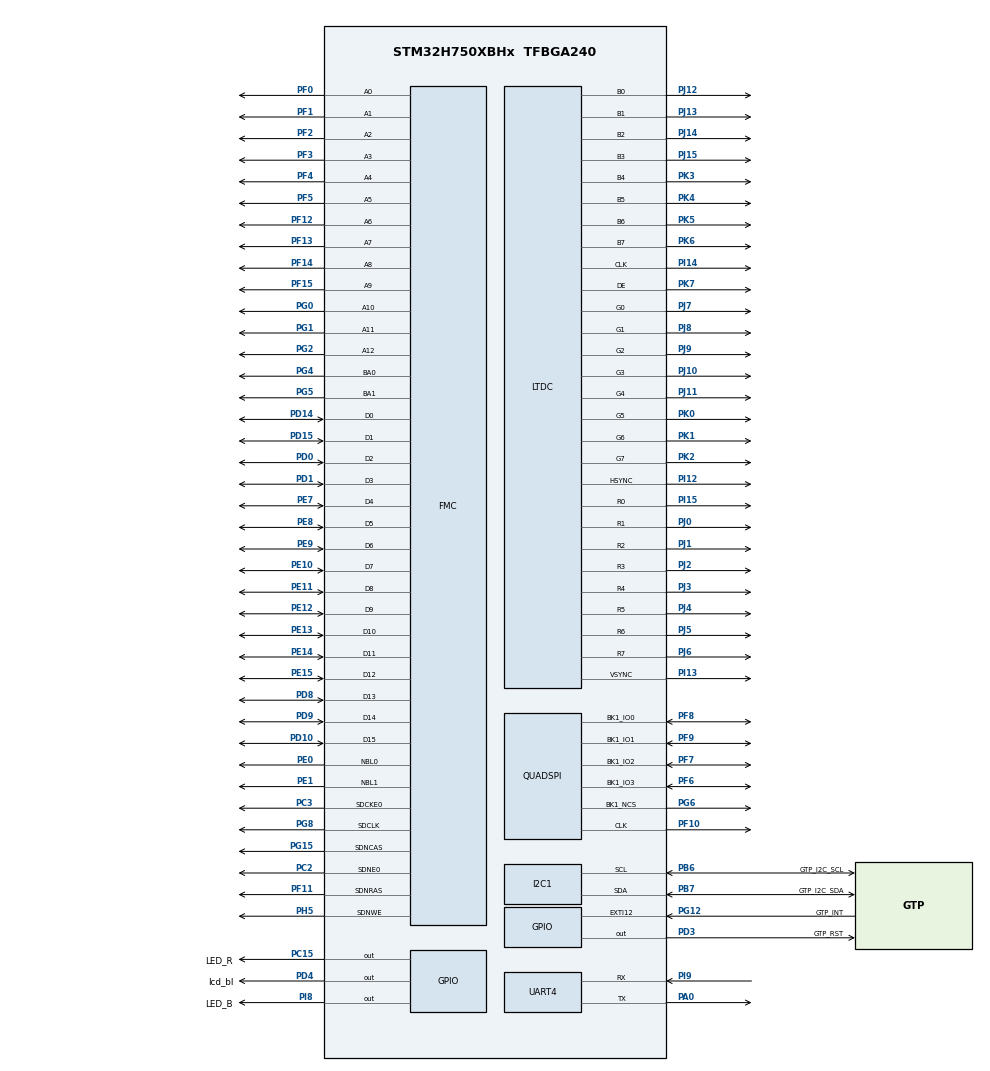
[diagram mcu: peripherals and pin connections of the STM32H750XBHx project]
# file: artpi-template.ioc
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DMA2D.ColorMode=DMA2D_OUTPUT_RGB565
FMC.CASLatency1=FMC_SDRAM_CAS_LATENCY_2
FMC.ColumnBitsNumber1=FMC_SDRAM_COLUMN_BITS_NUM_9
FMC.ExitSelfRefreshDelay1=8
FMC.LoadToActiveDelay1=2
FMC.RCDDelay1=2
FMC.RPDelay1=2
FMC.RowCycleDelay1=6
FMC.SDClockPeriod1=FMC_SDRAM_CLOCK_PERIOD_2
FMC.SelfRefreshTime1=6
I2C1.Timing=0x10C0ECFF
LTDC.ActiveW=800
LTDC.Alpha0_L0=0xff
LTDC.Alpha_L0=0xff
LTDC.FBStartAdress_L0=0xc0000000
LTDC.Green=255
LTDC.Green_L0=0
LTDC.HBP=140
LTDC.HFP=160
LTDC.HSync=20
LTDC.ImageHeight_L0=480
LTDC.ImageWidth_L0=800
LTDC.Layers=0
LTDC.PixelFormat_L0=LTDC_PIXEL_FORMAT_RGB565
LTDC.Red_L0=255
LTDC.VBP=12
LTDC.VFP=12
LTDC.VSync=3
LTDC.WindowX1_L0=800
LTDC.WindowY1_L0=480
Mcu.Family=STM32H7
Mcu.Name=STM32H750XBHx
Mcu.Package=TFBGA240
NVIC.EXTI15_10_IRQn=true\:0\:0\:false\:false\:true\:true\:true
NVIC.PriorityGroup=NVIC_PRIORITYGROUP_4
PA0.Mode=Asynchronous
PA0.Signal=UART4_TX
PA13\ (JTMS/SWDIO).Mode=Serial_Wire
PA13\ (JTMS/SWDIO).Signal=DEBUG_JTMS-SWDIO
PA14\ (JTCK/SWCLK).Mode=Serial_Wire
PA14\ (JTCK/SWCLK).Signal=DEBUG_JTCK-SWCLK
PB6.GPIO_Label=GTP_I2C_SCL
PB6.Mode=I2C
PB6.Signal=I2C1_SCL
PB7.GPIO_Label=GTP_I2C_SDA
PB7.Mode=I2C
PB7.Signal=I2C1_SDA
PC15-OSC32_OUT\ (OSC32_OUT).GPIO_Label=LED_R
PC15-OSC32_OUT\ (OSC32_OUT).Signal=GPIO_Output
PC2.Mode=SdramChipSelect1_1
PC2.Signal=FMC_SDNE0
PC3.Mode=SdramChipSelect1_1
PC3.Signal=FMC_SDCKE0
PD0.Signal=FMC_D2_DA2
PD1.Signal=FMC_D3_DA3
PD10.Signal=FMC_D15_DA15
PD14.Signal=FMC_D0_DA0
PD15.Signal=FMC_D1_DA1
PD3.GPIO_Label=GTP_RST
PD3.Signal=GPIO_Output
PD4.GPIO_Label=lcd_bl
PD4.Signal=GPIO_Output
PD8.Signal=FMC_D13_DA13
PD9.Signal=FMC_D14_DA14
PE0.Signal=FMC_NBL0
PE1.Signal=FMC_NBL1
PE10.Signal=FMC_D7_DA7
PE11.Signal=FMC_D8_DA8
PE12.Signal=FMC_D9_DA9
PE13.Signal=FMC_D10_DA10
PE14.Signal=FMC_D11_DA11
PE15.Signal=FMC_D12_DA12
PE7.Signal=FMC_D4_DA4
PE8.Signal=FMC_D5_DA5
PE9.Signal=FMC_D6_DA6
PF0.Signal=FMC_A0
PF1.Signal=FMC_A1
PF10.Mode=Single Bank 1
PF10.Signal=QUADSPI_CLK
PF11.Signal=FMC_SDNRAS
PF12.Signal=FMC_A6
PF13.Signal=FMC_A7
PF14.Signal=FMC_A8
PF15.Signal=FMC_A9
PF2.Signal=FMC_A2
PF3.Signal=FMC_A3
PF4.Signal=FMC_A4
PF5.Signal=FMC_A5
PF6.Mode=Single Bank 1
PF6.Signal=QUADSPI_BK1_IO3
PF7.Mode=Single Bank 1
PF7.Signal=QUADSPI_BK1_IO2
PF8.Mode=Single Bank 1
PF8.Signal=QUADSPI_BK1_IO0
PF9.Mode=Single Bank 1
PF9.Signal=QUADSPI_BK1_IO1
PG0.Signal=FMC_A10
PG1.Signal=FMC_A11
PG12.GPIO_Label=GTP_INT
PG12.Signal=GPXTI12
PG15.Signal=FMC_SDNCAS
PG2.Signal=FMC_A12
PG4.Signal=FMC_A14_BA0
PG5.Signal=FMC_A15_BA1
PG6.Mode=Single Bank 1
PG6.Signal=QUADSPI_BK1_NCS
PG8.Signal=FMC_SDCLK
PH0-OSC_IN\ (PH0).Mode=HSE-External-Oscillator
PH0-OSC_IN\ (PH0).Signal=RCC_OSC_IN
PH1-OSC_OUT\ (PH1).Mode=HSE-External-Oscillator
PH1-OSC_OUT\ (PH1).Signal=RCC_OSC_OUT
PH5.Signal=FMC_SDNWE
PI12.Mode=RGB888
PI12.Signal=LTDC_HSYNC
PI13.Mode=RGB888
PI13.Signal=LTDC_VSYNC
PI14.Mode=RGB888
PI14.Signal=LTDC_CLK
PI15.Mode=RGB888
PI15.Signal=LTDC_R0
PI8.GPIO_Label=LED_B
PI8.Signal=GPIO_Output
PI9.Mode=Asynchronous
PI9.Signal=UART4_RX
PJ0.Mode=RGB888
PJ0.Signal=LTDC_R1
PJ1.Mode=RGB888
PJ1.Signal=LTDC_R2
PJ10.Mode=RGB888
PJ10.Signal=LTDC_G3
PJ11.Mode=RGB888
PJ11.Signal=LTDC_G4
PJ12.Mode=RGB888
PJ12.Signal=LTDC_B0
PJ13.Mode=RGB888
PJ13.Signal=LTDC_B1
PJ14.Mode=RGB888
PJ14.Signal=LTDC_B2
PJ15.Mode=RGB888
PJ15.Signal=LTDC_B3
PJ2.Mode=RGB888
PJ2.Signal=LTDC_R3
PJ3.Mode=RGB888
PJ3.Signal=LTDC_R4
PJ4.Mode=RGB888
PJ4.Signal=LTDC_R5
PJ5.Mode=RGB888
PJ5.Signal=LTDC_R6
PJ6.Mode=RGB888
PJ6.Signal=LTDC_R7
PJ7.Mode=RGB888
PJ7.Signal=LTDC_G0
PJ8.Mode=RGB888
PJ8.Signal=LTDC_G1
PJ9.Mode=RGB888
PJ9.Signal=LTDC_G2
PK0.Mode=RGB888
PK0.Signal=LTDC_G5
PK1.Mode=RGB888
PK1.Signal=LTDC_G6
PK2.Mode=RGB888
PK2.Signal=LTDC_G7
PK3.Mode=RGB888
PK3.Signal=LTDC_B4
PK4.Mode=RGB888
PK4.Signal=LTDC_B5
PK5.Mode=RGB888
PK5.Signal=LTDC_B6
PK6.Mode=RGB888
PK6.Signal=LTDC_B7
PK7.Mode=RGB888
PK7.Signal=LTDC_DE
ProjectManager.HeapSize=0x200
ProjectManager.StackSize=0x400
ProjectManager.TargetToolchain=MDK-ARM V5.32
QUADSPI.ChipSelectHighTime=QSPI_CS_HIGH_TIME_5_CYCLE
QUADSPI.ClockPrescaler=1
QUADSPI.FifoThreshold=4
QUADSPI.FlashSize=23
QUADSPI.SampleShifting=QSPI_SAMPLE_SHIFTING_HALFCYCLE
RCC.ADCFreq_Value=64000000
RCC.APB1Freq_Value=100000000
RCC.APB2Freq_Value=100000000
RCC.APB3Freq_Value=100000000
RCC.APB4Freq_Value=100000000
RCC.CSICalibrationValue=16
RCC.CortexFreq_Value=400000000
RCC.D1PPRE=RCC_APB3_DIV2
RCC.D2PPRE1=RCC_APB1_DIV2
RCC.D2PPRE2=RCC_APB2_DIV2
RCC.D3PPRE=RCC_APB4_DIV2
RCC.DIVM1=5
RCC.DIVM2=25
RCC.DIVM3=5
RCC.DIVN1=160
RCC.DIVN2=128
RCC.DIVN3=50
RCC.DIVR3=10
RCC.HCLKFreq_Value=200000000
RCC.HPRE=RCC_HCLK_DIV2
RCC.HSICalibrationValue=32
RCC.PLLSourceVirtual=RCC_PLLSOURCE_HSE
RCC.ProductRev=revV
RCC.SYSCLKFreq_VALUE=400000000
RCC.SYSCLKSource=RCC_SYSCLKSOURCE_PLLCLK
RCC.USART234578CLockSelection=RCC_USART234578CLKSOURCE_CSI
RCC.USBFreq_Value=400000000
SH.FMC_A0.0=FMC_A0,13b-sda1
SH.FMC_A1.0=FMC_A1,13b-sda1
SH.FMC_A10.0=FMC_A10,13b-sda1
SH.FMC_A11.0=FMC_A11,13b-sda1
SH.FMC_A12.0=FMC_A12,13b-sda1
SH.FMC_A14_BA0.0=FMC_BA0,FourSdramBanks1
SH.FMC_A15_BA1.0=FMC_BA1,FourSdramBanks1
SH.FMC_A2.0=FMC_A2,13b-sda1
SH.FMC_A3.0=FMC_A3,13b-sda1
SH.FMC_A4.0=FMC_A4,13b-sda1
SH.FMC_A5.0=FMC_A5,13b-sda1
SH.FMC_A6.0=FMC_A6,13b-sda1
SH.FMC_A7.0=FMC_A7,13b-sda1
SH.FMC_A8.0=FMC_A8,13b-sda1
SH.FMC_A9.0=FMC_A9,13b-sda1
SH.FMC_D0_DA0.0=FMC_D0,sd-16b-d1
SH.FMC_D10_DA10.0=FMC_D10,sd-16b-d1
SH.FMC_D11_DA11.0=FMC_D11,sd-16b-d1
SH.FMC_D12_DA12.0=FMC_D12,sd-16b-d1
SH.FMC_D13_DA13.0=FMC_D13,sd-16b-d1
SH.FMC_D14_DA14.0=FMC_D14,sd-16b-d1
SH.FMC_D15_DA15.0=FMC_D15,sd-16b-d1
SH.FMC_D1_DA1.0=FMC_D1,sd-16b-d1
SH.FMC_D2_DA2.0=FMC_D2,sd-16b-d1
SH.FMC_D3_DA3.0=FMC_D3,sd-16b-d1
SH.FMC_D4_DA4.0=FMC_D4,sd-16b-d1
SH.FMC_D5_DA5.0=FMC_D5,sd-16b-d1
SH.FMC_D6_DA6.0=FMC_D6,sd-16b-d1
SH.FMC_D7_DA7.0=FMC_D7,sd-16b-d1
SH.FMC_D8_DA8.0=FMC_D8,sd-16b-d1
SH.FMC_D9_DA9.0=FMC_D9,sd-16b-d1
SH.FMC_NBL0.0=FMC_NBL0,Sd2ByteEnable1
SH.FMC_NBL1.0=FMC_NBL1,Sd2ByteEnable1
SH.FMC_SDCLK.0=FMC_SDCLK,13b-sda1
SH.FMC_SDNCAS.0=FMC_SDNCAS,13b-sda1
SH.FMC_SDNRAS.0=FMC_SDNRAS,13b-sda1
SH.FMC_SDNWE.0=FMC_SDNWE,13b-sda1
VP_CRC_VS_CRC.Mode=CRC_Activate
VP_DMA2D_VS_DMA2D.Mode=DMA2D_Activate
board=custom

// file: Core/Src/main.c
/* USER CODE BEGIN Header */
/**
  ******************************************************************************
  * @file           : main.c
  * @brief          : Main program body
  ******************************************************************************
  * @attention
  *
  * Copyright (c) 2022 STMicroelectronics.
  * All rights reserved.
  *
  * This software is licensed under terms that can be found in the LICENSE file
  * in the root directory of this software component.
  * If no LICENSE file comes with this software, it is provided AS-IS.
  *
  ******************************************************************************
  */
/* USER CODE END Header */
#include "main.h"
#include "crc.h"
#include "dma2d.h"
#include "i2c.h"
#include "ltdc.h"
#include "quadspi.h"
#include "usart.h"
#include "gpio.h"
#include "fmc.h"

/* USER CODE BEGIN Includes */
#include <stdio.h>
#include "EventRecorder.h"
#include "perf_counter.h"

#include "bsp_i2c_touch.h"
#include "bsp_touch_gtxx.h"
#include "core_delay.h"

#include "lvgl.h"
#include "demos/lv_demos.h"
/* USER CODE END Includes */

/* USER CODE BEGIN PD */
void MX_SDRAM_InitEx(void);

void lv_port_indev_init(void);
void lv_port_disp_init(void);

extern void GTP_TouchProcess(void);

static void touchpad_init(void);
static void touchpad_read(lv_indev_drv_t * indev_drv, lv_indev_data_t * data);
static bool touchpad_is_pressed(void);
static void touchpad_get_xy(lv_coord_t * x, lv_coord_t * y);
/* USER CODE END PD */

/* USER CODE BEGIN PV */
unsigned int *dispbuf  = (unsigned int*)0xc0000000;
unsigned int tpx=0,tpy=0,tppressed = 0;
/* USER CODE END PV */

void SystemClock_Config(void);
/* USER CODE BEGIN PFP */
extern void QSPI_MemoryMapped(void);
/* USER CODE END PFP */

int main(void)
{

  /* MCU Configuration--------------------------------------------------------*/

  /* Reset of all peripherals, Initializes the Flash interface and the Systick. */
  HAL_Init();

  /* Configure the system clock */
  SystemClock_Config();

  /* USER CODE BEGIN SysInit */
	SystemCoreClock = 400000000ul;//400MHz
	init_cycle_counter(false);
  /* USER CODE END SysInit */

  /* Initialize all configured peripherals */
  MX_GPIO_Init();
	MX_QUADSPI_Init();

  MX_FMC_Init();
  MX_UART4_Init();
  MX_I2C1_Init();
  MX_DMA2D_Init();
  MX_CRC_Init();
  MX_LTDC_Init();
  /* USER CODE BEGIN 2 */

	HAL_GPIO_WritePin(lcd_bl_GPIO_Port,lcd_bl_Pin,1);
	printf("START!\r\n");
	GTP_Init_Panel();

	EventRecorderInitialize(EventRecordAll, 1U);
	EventRecorderStart();
	int32_t time=get_system_ms();
	int32_t time5ms=get_system_ms();
	int32_t time500ms=get_system_ms();
	int i;
	lv_init();
	lv_port_disp_init();
	lv_port_indev_init();
memset(dispbuf,0x55,800*480*2);
lv_demo_music();
//lv_demo_widgets();
//lv_demo_stress();
//lv_demo_benchmark();
  /* USER CODE END 2 */

  /* Infinite loop */
  /* USER CODE BEGIN WHILE */
  while (1)
  {

		time=get_system_ms();

		if(time>=(time5ms+5))
		{
			lv_tick_inc(5);
			lv_timer_handler();
			time5ms=get_system_ms();
		}

		if(time>=(time500ms+100))
		{
//			memset(dispbuf,0xff,800*480*2);
//			memset(dispbuf,i++,800*480*2);

			HAL_GPIO_TogglePin(LED_R_GPIO_Port,LED_R_Pin);
			time500ms=get_system_ms();
		}

//		HAL_GPIO_TogglePin(lcd_bl_GPIO_Port,lcd_bl_Pin);
    /* USER CODE END WHILE */

  }
}

void SystemClock_Config(void)
{
  RCC_OscInitTypeDef RCC_OscInitStruct = {0};
  RCC_ClkInitTypeDef RCC_ClkInitStruct = {0};

  /** Supply configuration update enable
  */
  HAL_PWREx_ConfigSupply(PWR_LDO_SUPPLY);
  /** Configure the main internal regulator output voltage
  */
  __HAL_PWR_VOLTAGESCALING_CONFIG(PWR_REGULATOR_VOLTAGE_SCALE1);

  while(!__HAL_PWR_GET_FLAG(PWR_FLAG_VOSRDY)) {}
  /** Macro to configure the PLL clock source
  */
  __HAL_RCC_PLL_PLLSOURCE_CONFIG(RCC_PLLSOURCE_HSE);
  /** Initializes the RCC Oscillators according to the specified parameters
  * in the RCC_OscInitTypeDef structure.
  */
  RCC_OscInitStruct.OscillatorType = RCC_OSCILLATORTYPE_CSI|RCC_OSCILLATORTYPE_HSE;
  RCC_OscInitStruct.HSEState = RCC_HSE_ON;
  RCC_OscInitStruct.CSIState = RCC_CSI_ON;
  RCC_OscInitStruct.CSICalibrationValue = 16;
  RCC_OscInitStruct.PLL.PLLState = RCC_PLL_ON;
  RCC_OscInitStruct.PLL.PLLSource = RCC_PLLSOURCE_HSE;
  RCC_OscInitStruct.PLL.PLLM = 5;
  RCC_OscInitStruct.PLL.PLLN = 160;
  RCC_OscInitStruct.PLL.PLLP = 2;
  RCC_OscInitStruct.PLL.PLLQ = 2;
  RCC_OscInitStruct.PLL.PLLR = 2;
  RCC_OscInitStruct.PLL.PLLRGE = RCC_PLL1VCIRANGE_2;
  RCC_OscInitStruct.PLL.PLLVCOSEL = RCC_PLL1VCOWIDE;
  RCC_OscInitStruct.PLL.PLLFRACN = 0;
  if (HAL_RCC_OscConfig(&RCC_OscInitStruct) != HAL_OK)
  {
    Error_Handler();
  }
  /** Initializes the CPU, AHB and APB buses clocks
  */
  RCC_ClkInitStruct.ClockType = RCC_CLOCKTYPE_HCLK|RCC_CLOCKTYPE_SYSCLK
                              |RCC_CLOCKTYPE_PCLK1|RCC_CLOCKTYPE_PCLK2
                              |RCC_CLOCKTYPE_D3PCLK1|RCC_CLOCKTYPE_D1PCLK1;
  RCC_ClkInitStruct.SYSCLKSource = RCC_SYSCLKSOURCE_PLLCLK;
  RCC_ClkInitStruct.SYSCLKDivider = RCC_SYSCLK_DIV1;
  RCC_ClkInitStruct.AHBCLKDivider = RCC_HCLK_DIV2;
  RCC_ClkInitStruct.APB3CLKDivider = RCC_APB3_DIV2;
  RCC_ClkInitStruct.APB1CLKDivider = RCC_APB1_DIV2;
  RCC_ClkInitStruct.APB2CLKDivider = RCC_APB2_DIV2;
  RCC_ClkInitStruct.APB4CLKDivider = RCC_APB4_DIV2;

  if (HAL_RCC_ClockConfig(&RCC_ClkInitStruct, FLASH_LATENCY_2) != HAL_OK)
  {
    Error_Handler();
  }
}

/* USER CODE BEGIN 4 */
void LTDC_Color_Fill(uint16_t sx,uint16_t sy,uint16_t ex,uint16_t ey,uint16_t *color)
{
	uint32_t psx,psy,pex,pey;	//以LCD面板为基准的坐标系,不随横竖屏变化而变化
	uint32_t timeout=0;
	uint16_t offline;
	uint32_t addr;
	//坐标系转换
//	if(lcdltdc.dir)	//横屏
//	{
		psx=sx;psy=sy;
		pex=ex;pey=ey;
//	}else			//竖屏
//	{
//		psx=sy;psy=lcdltdc.pheight-ex-1;
//		pex=ey;pey=lcdltdc.pheight-sx-1;
//	}

	//width 800
	offline=800-(pex-psx+1);
	addr=((unsigned int)dispbuf[0]+2*(800*psy+psx));
	RCC->AHB1ENR|=1<<23;			//使能DM2D时钟
	DMA2D->CR=0<<16;				//存储器到存储器模式
	DMA2D->FGPFCCR=0X02;	//设置颜色格式 rgb565
	DMA2D->FGOR=0;					//前景层行偏移为0
	DMA2D->OOR=offline;				//设置行偏移
	DMA2D->CR&=~(1<<0);				//先停止DMA2D
	DMA2D->FGMAR=(unsigned int)color;		//源地址
	DMA2D->OMAR=addr;				//输出存储器地址
	DMA2D->NLR=(pey-psy+1)|((pex-psx+1)<<16);	//设定行数寄存器
	DMA2D->CR|=1<<0;				//启动DMA2D
	while((DMA2D->ISR&(1<<1))==0)	//等待传输完成
	{
		timeout++;
		if(timeout>0X1FFFFF)break;	//超时退出
	}
	DMA2D->IFCR|=1<<1;				//清除传输完成标志
}
#if 0
#define GLCD_WIDTH     800
#define GLCD_HEIGHT    480
#define LCD_DB_ADDR   0xC0000000
#define LCD_DB_PTR    ((volatile uint16_t *)LCD_DB_ADDR)

int32_t GLCD_DrawBitmap (uint32_t x,
                         uint32_t y,
                         uint32_t width,
                         uint32_t height,
                         const uint8_t *bitmap)
{
    volatile uint16_t *phwDes = LCD_DB_PTR + y * GLCD_WIDTH + x;
    const uint16_t *phwSrc = (const uint16_t *)bitmap;
    for (int_fast16_t i = 0; i < height; i++) {
        memcpy ((uint16_t *)phwDes, phwSrc, width * 2);
        phwSrc += width;
        phwDes += GLCD_WIDTH;
    }

    return 0;
}
#endif
void my_disp_flush(lv_disp_drv_t * disp, const lv_area_t * area, lv_color_t * color_p)
{

		uint32_t  height = area->y2 - area->y1;
		uint32_t  width= area->x2 - area->x1;
		uint32_t  x=area->x1;
		uint32_t  y=area->y1;

//		GLCD_DrawBitmap(x,width,y,height, (const uint8_t *)color_p);
//		LTDC_Color_Fill(area->x1,area->x2,area->y1,area->y2,(uint16_t*)color_p);

    lv_disp_flush_ready(disp);         /* Indicate you are ready with the flushing*/
}

void lv_port_disp_init(void)
{
	#define DISP_HOR_RES 800//800
	#define DISP_VER_RES 480//480

	static lv_disp_draw_buf_t draw_buf;
	//__attribute__((section(".ARM.__at_0x24000000")))
__attribute__((section(".ARM.__at_0xc0000000")))	static lv_color_t buf1[DISP_HOR_RES * DISP_VER_RES] ;// __attribute__((at(0Xc0001000)));
	/*Declare a buffer for 1/10 screen size*/
	lv_disp_draw_buf_init(&draw_buf, buf1, NULL, DISP_HOR_RES * DISP_VER_RES );
	/*Initialize the display buffer.*/

	static lv_disp_drv_t disp_drv;        /*Descriptor of a display driver*/
	lv_disp_drv_init(&disp_drv);          /*Basic initialization*/
	disp_drv.flush_cb = my_disp_flush;    /*Set your driver function*/
	disp_drv.draw_buf = &draw_buf;        /*Assign the buffer to the display*/
	disp_drv.hor_res = DISP_HOR_RES;   /*Set the horizontal resolution of the display*/
	disp_drv.ver_res = DISP_VER_RES;   /*Set the vertical resolution of the display*/
	disp_drv.full_refresh = 1;
	disp_drv.direct_mode = 1;
	lv_disp_drv_register(&disp_drv);      /*Finally register the driver*/
}

/*------------------
 * Touchpad
 * -----------------*/
lv_indev_t * indev_touchpad;

/*Initialize your touchpad*/
static void touchpad_init(void)
{
    /*Your code comes here*/
}

/*Will be called by the library to read the touchpad*/
static void touchpad_read(lv_indev_drv_t * indev_drv, lv_indev_data_t * data)
{
    static lv_coord_t last_x = 0;
    static lv_coord_t last_y = 0;

    /*Save the pressed coordinates and the state*/
    if(touchpad_is_pressed()) {
        touchpad_get_xy(&last_x, &last_y);
        data->state = LV_INDEV_STATE_PR;
    }
    else {
        data->state = LV_INDEV_STATE_REL;
    }

    /*Set the last pressed coordinates*/
    data->point.x = last_x;
    data->point.y = last_y;
}

/*Return true is the touchpad is pressed*/
static bool touchpad_is_pressed(void)
{
	if(tppressed == 1)
		return true;
    /*Your code comes here*/
	else
    return false;
}

/*Get the x and y coordinates if the touchpad is pressed*/
static void touchpad_get_xy(lv_coord_t * x, lv_coord_t * y)
{
	*x = tpx;
	*y = tpy;
    /*Your code comes here*/

//    (*x) = 0;
//    (*y) = 0;
}

void lv_port_indev_init(void)
{
	static lv_indev_drv_t indev_drv;

	lv_indev_drv_init(&indev_drv);
	indev_drv.type = LV_INDEV_TYPE_POINTER;
	indev_drv.read_cb = touchpad_read;
	indev_touchpad = lv_indev_drv_register(&indev_drv);
}

/* USER CODE END 4 */

void Error_Handler(void)
{
  __disable_irq();
  while (1)
  {
  }
}
